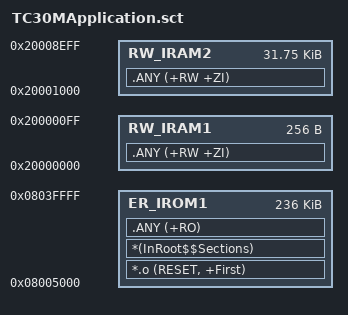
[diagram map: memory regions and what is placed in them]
; *************************************************************
; *** Scatter-Loading Description File generated by uVision ***
; *************************************************************

LR_IROM1 0x08005000 0x0003B000  {    ; load region size_region
  ER_IROM1 0x08005000 0x0003B000  {  ; load address = execution address
   *.o (RESET, +First)
   *(InRoot$$Sections)
   .ANY (+RO)
  }
  RW_IRAM1 0x20000000 0x00000100  {  ; RW data
   .ANY (+RW +ZI)
  }
  RW_IRAM2 0x20001000 0x00007F00  {
   .ANY (+RW +ZI)
  }
}

